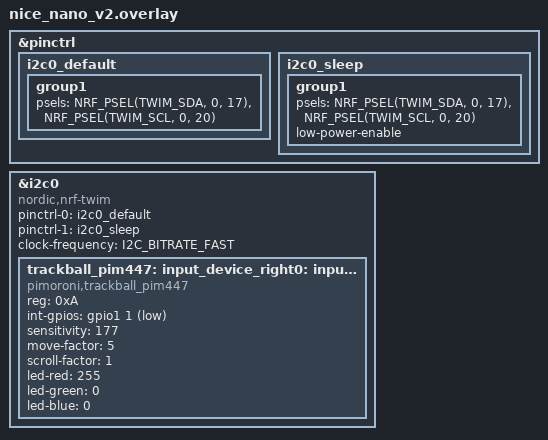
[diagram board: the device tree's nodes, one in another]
/**
 * Generated by Shield Wizard for ZMK
 * Applies to shield "jssplit_right" with board "nice_nano_v2" only
 */

//
// ======== i2c0 ========
//

// pin control for i2c0
// - SDA on D2
// - SCL on D3
&pinctrl {
    /* configuration for i2c0 device, default state */
    i2c0_default: i2c0_default {
        group1 {
            psels = <NRF_PSEL(TWIM_SDA, 0, 17)>,
                    <NRF_PSEL(TWIM_SCL, 0, 20)>;
        };
    };
    /* configuration for i2c0 device, sleep state */
    i2c0_sleep: i2c0_sleep {
        group1 {
            psels = <NRF_PSEL(TWIM_SDA, 0, 17)>,
                    <NRF_PSEL(TWIM_SCL, 0, 20)>;
            low-power-enable;
        };
    };
};
&i2c0 {
  compatible = "nordic,nrf-twim";
  status = "okay";
  pinctrl-0 = <&i2c0_default>;
  pinctrl-1 = <&i2c0_sleep>;
  pinctrl-names = "default", "sleep";
  clock-frequency = <I2C_BITRATE_FAST>;
};

// devices on i2c0
// was pimoroni_pim447: input_device_right0: input_device_right0@A { for my driver
&i2c0 {
    trackball_pim447: input_device_right0: input_device_right0@A {
        status = "okay";
        //compatible = "zmk,pimoroni-pim447"; //uncomment this row to get working for my driver I use before - 2-27-2026
        compatible = "pimoroni,trackball_pim447"; //this is for new driver
        reg = <0xA>;
        int-gpios = <&gpio1 1 (GPIO_ACTIVE_LOW | GPIO_PULL_UP)>;
        //pim447_disable_sleep; //see if this disables the sleeping of the right


        //Everything below this is for the new driver
        sensitivity = <177>;  /* Range: 1-255 */
        move-factor = <5>;   /* Range: 1-10, scales cursor movement speed */
        scroll-factor = <1>; /* Range: 1-10, scales scrolling speed */
        
        /* Optional LED color (RGB values 0-255) */
        led-red = <255>;
        led-green = <0>;
        led-blue = <0>;
        
        /* Optional axis inversion */
        /* invert-x; */   /* Uncomment to invert X axis */
        /* invert-y; */   /* Uncomment to invert Y axis */
    };
};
